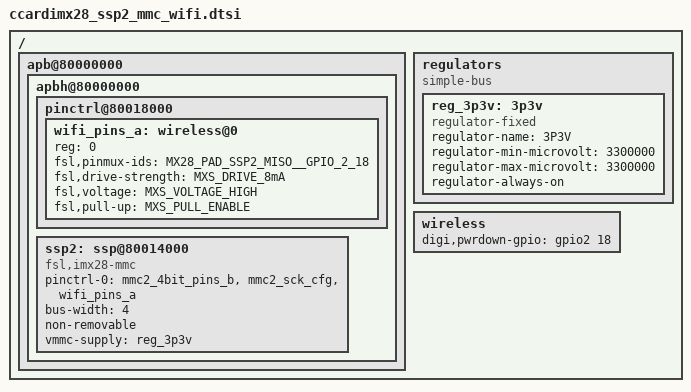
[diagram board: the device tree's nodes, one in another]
/*
 * Copyright 2013 Digi International, Inc.
 *
 * The code contained herein is licensed under the GNU General Public
 * License. You may obtain a copy of the GNU General Public License
 * Version 2 or later at the following locations:
 *
 * http://www.opensource.org/licenses/gpl-license.html
 * http://www.gnu.org/copyleft/gpl.html
 */

/ {
	apb@80000000 {
		apbh@80000000 {
			pinctrl@80018000 {
				wifi_pins_a: wireless@0 {
					reg = <0>;
					fsl,pinmux-ids = <
						MX28_PAD_SSP2_MISO__GPIO_2_18
					>;
					fsl,drive-strength = <MXS_DRIVE_8mA>;
					fsl,voltage = <MXS_VOLTAGE_HIGH>;
					fsl,pull-up = <MXS_PULL_ENABLE>;
				};
			};

			ssp2: ssp@80014000 {
				compatible = "fsl,imx28-mmc";
				pinctrl-names = "default";
				pinctrl-0 = <&mmc2_4bit_pins_b
					     &mmc2_sck_cfg
					     &wifi_pins_a>;
				bus-width = <4>;
				non-removable;
				vmmc-supply = <&reg_3p3v>;
				status = "okay";
			};
		};
	};

	regulators {
		compatible = "simple-bus";

		reg_3p3v: 3p3v {
			compatible = "regulator-fixed";
			regulator-name = "3P3V";
			regulator-min-microvolt = <3300000>;
			regulator-max-microvolt = <3300000>;
			regulator-always-on;
		};
	};

	wireless {
		digi,pwrdown-gpio = <&gpio2 18 0>;
		/* U-Boot will fill in the MAC address here */
	};
};
